# CH32H417 register map
Vendor: WCH Ltd.; File version: 1.2
Registers are 32-bit, read-write, reset 0x0 unless marked. A register's access mark holds for its fields unless they carry their own. Offsets are from the block's base; [hi:lo] are bit positions; {n}, {i} and the like mark numbered series.

## PWR — Power control
Base 0x40007000
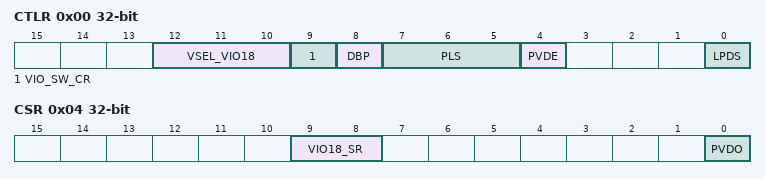
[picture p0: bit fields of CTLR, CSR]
0x00 CTLR — Power control register (PWR_CTRL)
  [12:10] VSEL_VIO18 — VIO18 power supply adjustment position
  [9] VIO_SW_CR — VIO18 power regulation mode selection
  [8] DBP — Disable Backup Domain write protection
  [7:5] PLS — PVD Level Selection
  [4] PVDE — Power Voltage Detector Enable
  [0] LPDS — Low Power Deep Sleep
0x04 CSR ro — Power control register (PWR_CSR)
  [9:8] VIO18_SR — VIO18 power supply initial status indicator
  [0] PVDO — PVD Output

## CRC — CRC calculation unit
Base 0x40023000
0x00 DATAR reset 0xFFFFFFFF — Data register
  [31:0] DR — Data Register
0x04 IDATAR 8-bit — Independent Data register
  [7:0] IDR
0x08 CTLR wo — Control register
  [0] RESET — Reset bit

## RTC — Real time clock
Base 0x40002800
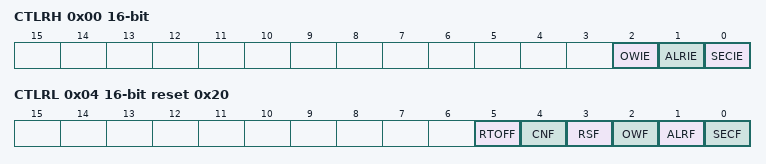
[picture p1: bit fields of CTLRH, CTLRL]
0x00 CTLRH 16-bit — RTC Control Register High
  [2] OWIE — Overflow interrupt Enable
  [1] ALRIE — Alarm interrupt Enable
  [0] SECIE — Second interrupt Enable
0x04 CTLRL 16-bit access per field reset 0x20 — RTC Control Register Low
  [5] RTOFF ro — RTC operation OFF
  [4] CNF rw — Configuration Flag
  [3] RSF rw — Registers Synchronized Flag
  [2] OWF rw — Overflow Flag
  [1] ALRF rw — Alarm Flag
  [0] SECF rw — Second Flag
0x08 PSCRH 16-bit wo — RTC Prescaler Load Register High
  [3:0] PRL
0x0C PSCRL 16-bit wo — RTC Prescaler Load Register Low
  [15:0] PRL — RTC Prescaler Divider Register Low
0x10 DIVH 16-bit ro — RTC Prescaler Divider Register High
  [3:0] DIV — RTC prescaler divider register high
0x14 DIVL 16-bit ro — RTC Prescaler Divider Register Low
  [15:0] DIV — RTC prescaler divider register Low
0x18 CNTH 16-bit — RTC Counter Register High
  [15:0] CNTH — RTC counter register high
0x1C CNTL 16-bit — RTC Counter Register Low
  [15:0] CNTL — RTC counter register Low
0x20 ALRMH 16-bit wo — RTC Alarm Register High
  [15:0] ALR — RTC alarm register high
0x24 ALRML 16-bit wo — RTC Alarm Register Low
  [15:0] ALR — RTC alarm register low

## IWDG — Independent watchdog
Base 0x40003000
0x00 CTLR wo — Key register (IWDG_CTLR)
  [15:0] KEY — Key value
0x04 PSCR — Prescaler register (IWDG_PSCR)
  [2:0] PR — Prescaler divider
0x08 RLDR reset 0xFFF — Reload register (IWDG_RLDR)
  [11:0] RL — Watchdog counter reload value
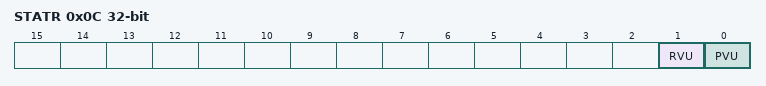
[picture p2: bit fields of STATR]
0x0C STATR ro — Status register (IWDG_SR)
  [1] RVU — Watchdog counter reload value update
  [0] PVU — Watchdog prescaler value update

## WWDG — Window watchdog
Base 0x40002C00
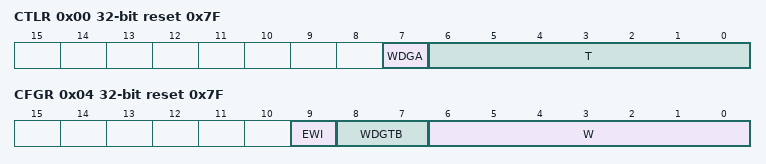
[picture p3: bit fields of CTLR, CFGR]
0x00 CTLR reset 0x7F — Control register (WWDG_CR)
  [7] WDGA — Activation bit
  [6:0] T — 7-bit counter (MSB to LSB)
0x04 CFGR reset 0x7F — Configuration register (WWDG_CFGR)
  [9] EWI — Early Wakeup Interrupt
  [8:7] WDGTB — Timer Base
  [6:0] W — 7-bit window value
0x08 STATR — Status register (WWDG_SR)
  [0] EWIF — Early Wakeup Interrupt Flag

## GPIOA — General purpose I/O
Base 0x40010800
Same registers: GPIOB 0x40010C00, GPIOC 0x40011000, GPIOD 0x40011400, GPIOE 0x40011800, GPIOF 0x40011C00
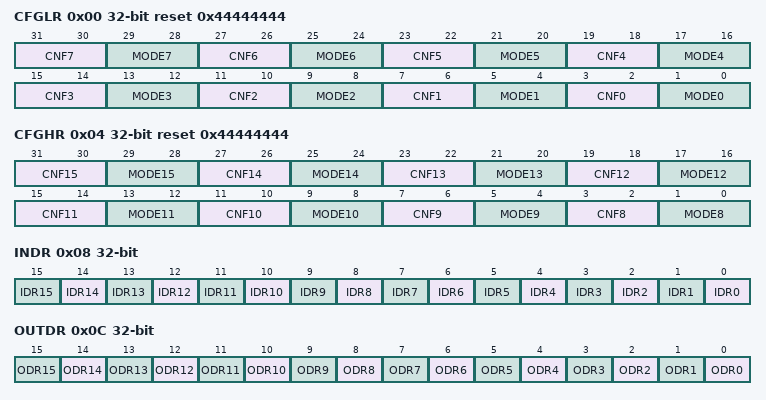
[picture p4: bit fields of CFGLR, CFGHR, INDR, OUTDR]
0x00 CFGLR reset 0x44444444 — Port configuration register low (GPIOn_CFGLR)
  [31:30] CNF7 — Port n.7 configuration bits
  [29:28] MODE7 — Port n.7 mode bits
  [27:26] CNF6 — Port n.6 configuration bits
  [25:24] MODE6 — Port n.6 mode bits
  [23:22] CNF5 — Port n.5 configuration bits
  [21:20] MODE5 — Port n.5 mode bits
  [19:18] CNF4 — Port n.4 configuration bits
  [17:16] MODE4 — Port n.4 mode bits
  [15:14] CNF3 — Port n.3 configuration bits
  [13:12] MODE3 — Port n.3 mode bits
  [11:10] CNF2 — Port n.2 configuration bits
  [9:8] MODE2 — Port n.2 mode bits
  [7:6] CNF1 — Port n.1 configuration bits
  [5:4] MODE1 — Port n.1 mode bits
  [3:2] CNF0 — Port n.0 configuration bits
  [1:0] MODE0 — Port n.0 mode bits
0x04 CFGHR reset 0x44444444 — Port configuration register high (GPIOn_CFGHR)
  [31:30] CNF15 — Port n.15 configuration bits
  [29:28] MODE15 — Port n.15 mode bits
  [27:26] CNF14 — Port n.14 configuration bits
  [25:24] MODE14 — Port n.14 mode bits
  [23:22] CNF13 — Port n.13 configuration bits
  [21:20] MODE13 — Port n.13 mode bits
  [19:18] CNF12 — Port n.12 configuration bits
  [17:16] MODE12 — Port n.12 mode bits
  [15:14] CNF11 — Port n.11 configuration bits
  [13:12] MODE11 — Port n.11 mode bits
  [11:10] CNF10 — Port n.10 configuration bits
  [9:8] MODE10 — Port n.10 mode bits
  [7:6] CNF9 — Port n.9 configuration bits
  [5:4] MODE9 — Port n.9 mode bits
  [3:2] CNF8 — Port n.8 configuration bits
  [1:0] MODE8 — Port n.8 mode bits
0x08 INDR ro — Port input data register (GPIOn_INDR)
  [n] IDR{n} (n=0..15) — Port input data
0x0C OUTDR — Port output data register (GPIOn_OUTDR)
  [n] ODR{n} (n=0..15) — Port output data
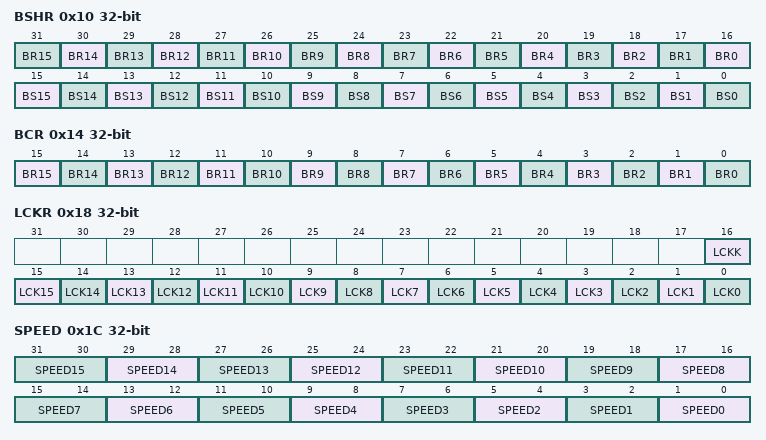
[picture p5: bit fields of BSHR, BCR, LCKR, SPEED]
0x10 BSHR wo — Port bit set/reset register (GPIOn_BSHR)
  [n+16] BR{n} (n=0..15) — Reset bit {n}
  [n] BS{n} (n=3..15) — Set bit {n}
  [2] BS2 — Set bit 1
  [1] BS1 — Set bit 1
  [0] BS0 — Set bit 0
0x14 BCR wo — Port bit reset register (GPIOn_BCR)
  [n] BR{n} (n=3..15) — Reset bit {n}
  [2] BR2 — Reset bit 1
  [1] BR1 — Reset bit 1
  [0] BR0 — Reset bit 0
0x18 LCKR — Port configuration lock register
  [16] LCKK — Lock key
  [n] LCK{n} (n=0..15) — Port A Lock bit {n}
0x1C SPEED — Port speed register (GPIOx_SPEED)
  [2n+1:2n] SPEED{n} (n=0..15) — Port x pin {n} speed: 00=10MHz, 01=50MHz, 10=100MHz, 11=180MHz
